AUTOSAR XML (schema 4-0-3)
package /ComponentTypes
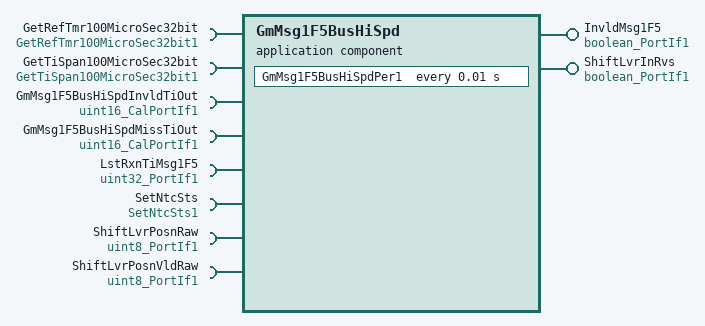
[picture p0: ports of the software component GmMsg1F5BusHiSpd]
  application sw component type GmMsg1F5BusHiSpd
    provide port InvldMsg1F5: nonqueued-sender-com-spec{data-element=Logl, init-value=0}, provided-interface=boolean_PortIf1
    provide port ShiftLvrInRvs: nonqueued-sender-com-spec{data-element=Logl, init-value=0}, provided-interface=boolean_PortIf1
    8 x require port:
      GetRefTmr100MicroSec32bit: required-interface=GetRefTmr100MicroSec32bit1
      GetTiSpan100MicroSec32bit: required-interface=GetTiSpan100MicroSec32bit1
      GmMsg1F5BusHiSpdInvldTiOut: parameter-require-com-spec{init-value=500, parameter=Val}, required-interface=uint16_CalPortIf1
      GmMsg1F5BusHiSpdMissTiOut: parameter-require-com-spec{init-value=500, parameter=Val}, required-interface=uint16_CalPortIf1
      LstRxnTiMsg1F5: nonqueued-receiver-com-spec{data-element=Val, filter=data-filter-type=ALWAYS, init-value=0}, required-interface=uint32_PortIf1
      SetNtcSts: required-interface=SetNtcSts1
      ShiftLvrPosnRaw: nonqueued-receiver-com-spec{data-element=Val, filter=data-filter-type=ALWAYS, init-value=0}, required-interface=uint8_PortIf1
      ShiftLvrPosnVldRaw: nonqueued-receiver-com-spec{data-element=Val, filter=data-filter-type=ALWAYS, init-value=0}, required-interface=uint8_PortIf1
    behavior GmMsg1F5BusHiSpd_InternalBehavior: data-type-mapping=Nexteer
      ar-typed-per-instance-memorys:
        data GmMsg1F5BusHiSpdInvldTmr: sw-calibration-access=READ-ONLY, type=uint32
        data GmMsg1F5BusHiSpdPrevShiftLvrInRvs: sw-calibration-access=READ-ONLY, type=boolean
      timing event TMT_GM0C9HSPer1: start-on-event=GmMsg1F5BusHiSpdPer1, period=0.01
      runnable GmMsg1F5BusHiSpdPer1
        data-receive-point-by-arguments:
          access REC_Msg0C9HSLstRxnTi_Val: accessed-variable=LstRxnTiMsg1F5.Val
          access REC_ShiftLvrPosnRaw_Val: accessed-variable=ShiftLvrPosnRaw.Val
          access REC_ShiftLvrPosnVldRaw_Val: accessed-variable=ShiftLvrPosnVldRaw.Val
        data-send-points:
          access SEND_InvldMsg1F5_Logl: accessed-variable=InvldMsg1F5.Logl
          access SEND_ShiftLvrInRvs_Logl: accessed-variable=ShiftLvrInRvs.Logl
        sync call SC_GetRefTmr100MicroSec32bit_Oper: operation=GetRefTmr100MicroSec32bit.Oper, timeout=0
        sync call SC_GetTiSpan100MicroSec32bit_Oper: operation=GetTiSpan100MicroSec32bit.Oper, timeout=0
        sync call SC_SetNtcSts_Oper: operation=SetNtcSts.Oper, timeout=0
  swc implementation GmMsg1F5BusHiSpd_Implementation: behavior=GmMsg1F5BusHiSpd_InternalBehavior
    code-descriptors:
      code Default: artifact-descriptors=autosar-engineering-object={short-label=Default, category=SWSRC}
